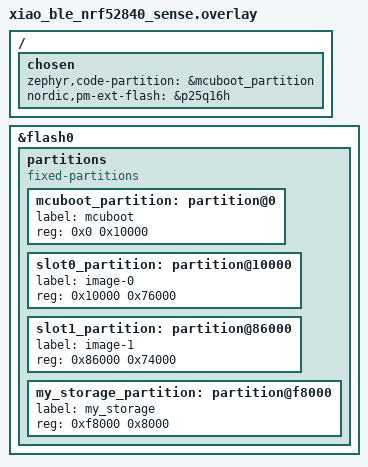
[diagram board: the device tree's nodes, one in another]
/*
 * Copyright (c) 2023 Nordic Semiconductor ASA
 *
 * SPDX-License-Identifier: LicenseRef-Nordic-5-Clause
 */

/ {
	chosen {
		zephyr,code-partition = &mcuboot_partition;
		nordic,pm-ext-flash = &p25q16h;
	};
};

&flash0 {
    partitions {
        compatible = "fixed-partitions";
        #address-cells = <1>;
        #size-cells = <1>;

        mcuboot_partition: partition@0 {
            label = "mcuboot";
            reg = <0x0 0x10000>;  /* increased to 64 KB */
        };

        slot0_partition: partition@10000 {
            label = "image-0";
            reg = <0x10000 0x76000>;  /* adjusted start and size */
        };

        slot1_partition: partition@86000 {
            label = "image-1";
            reg = <0x86000 0x74000>;
        };

        my_storage_partition: partition@f8000 {
            label = "my_storage";
            reg = <0xf8000 0x8000>;
        };
    };
};
